# STM32U545 register map
File version: 1.0
CPU: CM33 r0p1, little endian, MPU, FPU, 4 interrupt priority bits
Registers are 32-bit, read-write, reset 0x0 unless marked. A register's access mark holds for its fields unless they carry their own. Offsets are from the block's base; [hi:lo] are bit positions; {n}, {i} and the like mark numbered series; 'fields as' and 'values as' point back to an identical list; <NAME> marks a mode.

## RCC (part 1 of 3) — Reset and clock control
Base 0x46020C00
Same registers: SEC_RCC 0x56020C00
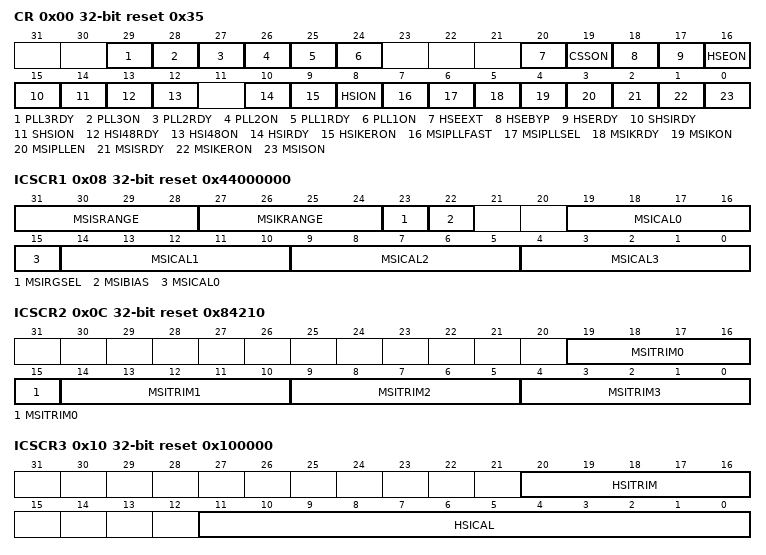
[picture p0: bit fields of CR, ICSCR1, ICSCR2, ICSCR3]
0x00 CR access per field reset 0x35 — RCC clock control register
  [29] PLL3RDY ro — PLL3 clock ready flag This bit is set by hardware to indicate that the PLL3 is locked.
    0=Unlocked (PLL3 unlocked); 1=Locked (PLL3 locked)
  [28] PLL3ON rw — PLL3 enable This bit is set and cleared by software to enable PLL3. It is cleared by hardware when entering Stop, Standby, or Shutdown mode.
    0=Disabled (PLL3 OFF); 1=Enabled (PLL3 ON)
  [27] PLL2RDY ro — PLL2 clock ready flag This bit is set by hardware to indicate that the PLL2 is locked.
    0=Unlocked (PLL2 unlocked); 1=Locked (PLL2 locked)
  [26] PLL2ON rw — PLL2 enable This bit is set and cleared by software to enable PLL2. It is cleared by hardware when entering Stop, Standby, or Shutdown mode.
    0=Disabled (PLL2 OFF); 1=Enabled (PLL2 ON)
  [25] PLL1RDY ro — PLL1 clock ready flag This bit is set by hardware to indicate that the PLL1 is locked.
    0=Unlocked (PLL1 unlocked); 1=Locked (PLL1 locked)
  [24] PLL1ON rw — PLL1 enable This bit is set and cleared by software to enable the main PLL. It is cleared by hardware when entering Stop, Standby, or Shutdown mode. This bit cannot be reset if the PLL1 clock is used as the system clock.
    0=Disabled (PLL1 OFF); 1=Enabled (PLL1 ON)
  [20] HSEEXT rw — HSE external clock bypass mode This bit is set and reset by software to select the external clock mode in bypass mode. External clock mode must be configured with HSEON bit to be used by the device. This bit can be written only if the HSE oscillator is disabled. This bit is active only if the HSE bypass mode is enabled.
    0=Analog (external HSE clock analog mode); 1=Digital (external HSE clock digital mode (through I/O Schmitt trigger))
  [19] CSSON rw — Clock security system enable This bit is set by software to enable the clock security system. When CSSON is set, the clock detector is enabled by hardware when the HSE oscillator is ready, and disabled by hardware if a HSE clock failure is detected. This bit is set only and is cleared by reset.
    0=Disabled (Clock security system OFF (clock detector OFF)); 1=Enabled (Clock security system ON (Clock detector ON if the HSE oscillator is stable, OFF if not))
  [18] HSEBYP rw — HSE crystal oscillator bypass This bit is set and cleared by software to bypass the oscillator with an external clock. The�external clock must be enabled with the HSEON bit set, to be used by the device. This�bit can be written only if the HSE oscillator is disabled.
    0=NotBypassed (HSE crystal oscillator not bypassed); 1=Bypassed (HSE crystal oscillator bypassed with external clock)
  [17] HSERDY ro — HSE clock ready flag This bit is set by hardware to indicate that the HSE oscillator is stable. Note: Once the HSEON bit is cleared, HSERDY goes low after six HSE clock cycles.
    0=NotReady (HSE oscillator not ready); 1=Ready (HSE oscillator ready)
  [16] HSEON rw — HSE clock enable This bit is set and cleared by software. It is cleared by hardware to stop the HSE oscillator when entering Stop, Standby, or Shutdown mode. This bit cannot be reset if the HSE oscillator is used directly or indirectly as the system clock.
    0=Disabled (HSE oscillator off); 1=Enabled (HSE oscillator on)
  [15] SHSIRDY ro — SHSI clock ready flag This bit is set by hardware to indicate that the SHSI oscillator is stable. It is set only when SHSI is enabled by software (by setting SHSION). Note: Once the SHSION bit is cleared, SHSIRDY goes low after six SHSI clock cycles.
    0=NotReady (SHSI oscillator not ready); 1=Ready (SHSI oscillator ready)
  [14] SHSION rw — SHSI clock enable This bit is set and cleared by software. It is cleared by hardware to stop the SHSI when entering in Stop, Standby, or Shutdown modes.
    0=Disabled (SHSI oscillator off); 1=Enabled (SHSI oscillator on)
  [13] HSI48RDY ro — HSI48 clock ready flag This bit is set by hardware to indicate that HSI48 oscillator is stable. Itis set only when HSI48 is enabled by software (by setting HSI48ON).
    0=NotReady (HSI48 oscillator not ready); 1=Ready (HSI48 oscillator ready)
  [12] HSI48ON rw — HSI48 clock enable This bit is set and cleared by software. It is cleared by hardware to stop the HSI48 when entering in Stop, Standby, or Shutdown modes.
    0=Disabled (HSI48 oscillator off); 1=Enabled (HSI48 oscillator on)
  [10] HSIRDY ro — HSI16 clock ready flag This bit is set by hardware to indicate that HSI16 oscillator is stable. It is set only when HSI16 is enabled by software (by setting HSION). Note: Once the HSION bit is cleared, HSIRDY goes low after six HSI16 clock cycles.
    0=NotReady (HSI16 oscillator not ready); 1=Ready (HSI16 oscillator ready)
  [9] HSIKERON rw — HSI16 enable for some peripheral kernels This bit is set and cleared by software to force HSI16 ON even in Stop modes. Keeping HSI16 on in Stop mode allows the communication speed not to be reduced by the HSI16 startup time. This bit has no effect on HSION value. Refer to Section�11.4.24 for more details. This bit must be configured at 0 before entering Stop 3 mode.
    0=NotForced (No effect on HSI16 oscillator); 1=Forced (HSI16 oscillator forced on even in Stop mode)
  [8] HSION rw — HSI16 clock enable This bit is set and cleared by software. It is cleared by hardware to stop the HSI16 oscillator when entering Stop, Standby, or Shutdown mode. This bit is set by hardware to force the�HSI16 oscillator on when STOPWUCK = 1 when leaving Stop modes, or in case of failure of the HSE crystal oscillator. This bit is set by hardware if the HSI16 is used directly or indirectly as system clock.
    0=Disabled (HSI16 oscillator off); 1=Enabled (HSI16 oscillator on)
  [7] MSIPLLFAST rw — MSI PLL mode fast startup This bit is set and reset by software to enable/disable the fast PLL mode start-up of the MSI clock source. This bit is used only if PLL mode is selected (MSIPLLEN = 1). The fast start-up feature is not active the first time the PLL mode is selected. The�fast start-up is active when the MSI in PLL mode returns from switch off.
    0=Normal (MSI PLL normal start-up); 1=Fast (MSI PLL fast start-up)
  [6] MSIPLLSEL rw — MSI clock with PLL mode selection This bit is set and cleared by software to select which MSI output clock uses the PLL mode. It�can be written only when the MSI PLL mode is disabled (MSIPLLEN = 0). Note: If the MSI kernel clock output uses the same oscillator source than the MSI system clock output, then the PLL mode is applied to both clock outputs.
    0=MSIK (PLL mode applied to MSIK (MSI kernel) clock output); 1=MSIS (PLL mode applied to MSIS (MSI system) clock output)
  [5] MSIKRDY ro — MSIK clock ready flag This bit is set by hardware to indicate that the MSIK is stable. It is set only when MSI kernel oscillator is enabled by software by setting MSIKON. Note: Once MSIKON bit is cleared, MSIKRDY goes low after six MSIK oscillator clock cycles.
    0=NotReady (MSIK (MSI kernel) oscillator not ready); 1=Ready (MSIK (MSI kernel) oscillator ready)
  [4] MSIKON rw — MSIK clock enable This bit is set and cleared by software. It is cleared by hardware to stop the MSIK when entering Stop, Standby, or Shutdown mode. This bit is set by hardware to force the MSIK oscillator ON when exiting Standby or Shutdown mode. It is set by hardware to force the MSIK oscillator on when STOPWUCK = 0 or STOPKERWUCK�=�0 when exiting Stop modes, or in case of a failure of the HSE oscillator.
    0=Disabled (MSIK (MSI kernel) oscillator disabled); 1=Enabled (MSIK (MSI kernel) oscillator enabled)
  [3] MSIPLLEN rw — MSI clock PLL-mode enable This bit is set and cleared by software to enable/disable the PLL part of the MSI clock source. MSIPLLEN must be enabled after LSE is enabled (LSEON enabled) and ready (LSERDY set by hardware). A hardware protection prevents from enabling MSIPLLEN if LSE is not ready. This bit is cleared by hardware when LSE is disabled (LSEON = 0) or when the CSS on LSE detects a LSE failure (see RCC_CSR).
    0=Disabled (MSI PLL-mode OFF); 1=Enabled (MSI PLL-mode ON)
  [2] MSISRDY ro — MSIS clock ready flag This bit is set by hardware to indicate that the MSIS oscillator is stable. It is set only when MSIS is enabled by software (by setting MSISON). Note: Once the MSISON bit is cleared, MSISRDY goes low after six MSIS clock cycles.
    0=NotReady (MSIS (MSI system) oscillator not ready); 1=Ready (MSIS (MSI system) oscillator ready)
  [1] MSIKERON rw — MSI enable for some peripheral kernels This bit is set and cleared by software to force MSI ON even in Stop modes. Keeping the MSI on in Stop mode allows the communication speed not to be reduced by the MSI startup time. This bit has no effect on MSISON and MSIKON values (see Section�11.4.24 for more details). This bit must be configured at 0 before entering Stop 3 mode.
    0=NotForced (No effect on MSI oscillator); 1=Forced (MSI oscillator forced ON even in Stop mode)
  [0] MSISON rw — MSIS clock enable This bit is set and cleared by software. It is cleared by hardware to stop the MSIS oscillator when entering Stop, Standby or Shutdown mode. This bit is set by hardware to force the�MSIS oscillator on when exiting Standby or Shutdown mode. It is set by hardware to force the MSIS oscillator ON when STOPWUCK = 0 when exiting Stop modes, or in case of a failure of the HSE oscillator. Set by hardware when used directly or indirectly as system clock.
    0=Disabled (MSIS (MSI system) oscillator off); 1=Enabled (MSIS (MSI system) oscillator on)
0x08 ICSCR1 access per field reset 0x44000000 (reset mask 0xFFF00000) — RCC internal clock sources calibration register 1
  [31:28] MSISRANGE rw — MSIS clock ranges These bits are configured by software to choose the frequency range of MSIS oscillator when MSIRGSEL is set. 16 frequency ranges are available: Note: MSISRANGE can be modified when MSIS is off (MSISON = 0) or when MSIS is ready (MSISRDY�=�1). MSISRANGE must NOT be modified when MSIS is on and NOT ready (MSISON�=�1 and MSISRDY�=�0) Note: MSISRANGE is kept when the device wakes up from Stop mode, except when the�MSIS range is above 24 MHz. In this case MSISRANGE is changed by hardware into range 2 (24 MHz).
    0=f_48MHz (Range 0 around 48 MHz); 1=f_24MHz (Range 1 around 24 MHz); 2=f_16MHz (Range 2 around 16 MHz); 3=f_12MHz (Range 3 around 12 MHz); 4=f_4MHz (Range 4 around 4 MHz); 5=f_2MHz (Range 5 around 2 MHz); 6=f_1_333MHz (Range 6 around 1.33 MHz); 7=f_1MHz (Range 7 around 1 MHz); 8=f_3_072MHz (Range 8 around 3.072 MHz); 9=f_1_536MHz (Range 9 around 1.536 MHz); 10=f_1_024MHz (Range 10 around 1.024 MHz); 11=f_768kHz (Range 11 around 768 kHz); 12=f_400kHz (Range 12 around 400 kHz); 13=f_200kHz (Range 13 around 200 kHz); 14=f_133kHz (Range 14 around 133 kHz); 15=f_100kHz (Range 15 around 100 kHz)
  [27:24] MSIKRANGE rw — MSIK clock ranges These bits are configured by software to choose the frequency range of MSIK oscillator when MSIRGSEL is set. 16 frequency ranges are available: Note: MSIKRANGE can be modified when MSIK is off (MSISON = 0) or when MSIK is ready (MSIKRDY�=�1). MSIKRANGE must NOT be modified when MSIK is on and NOT ready (MSIKON = 1 and MSIKRDY = 0) Note: MSIKRANGE is kept when the device wakes up from Stop mode, except when the�MSIK range is above 24 MHz. In this case MSIKRANGE is changed by hardware into�range 2 (24 MHz).
    values as MSISRANGE
  [23] MSIRGSEL rw — MSI clock range selection This bit is set by software to select the MSIS and MSIK clocks range with MSISRANGE[3:0] and MSIKRANGE[3:0]. Write 0 has no effect. After exiting Standby or Shutdown mode, or after a reset, this bit is at 0 and the MSIS and MSIK ranges are provided by MSISSRANGE[3:0] and MSIKSRANGE[3:0] in RCC_CSR.
    0=CSR (MSIS/MSIK ranges provided by MSISSRANGE[3:0] and MSIKSRANGE[3:0] in RCC_CSR); 1=ICSCR1 (MSIS/MSIK ranges provided by MSISRANGE[3:0] and MSIKRANGE[3:0] in RCC_ICSCR1)
  [22] MSIBIAS rw — MSI bias mode selection This bit is set by software to select the MSI bias mode. By default, the MSI bias is in�continuous mode in order to maintain the output clocks accuracy. Setting this bit reduces the MSI consumption when the regulator is in range 4, or when the device is in Stop 1 or Stop�2 mode, but it�decreases the MSI accuracy
    0=Continuous (MSI bias continuous mode (clock accuracy fast settling time)); 1=Sampling (MSI bias sampling mode when the regulator is in range 4, or when the device is in Stop 1 or Stop 2 (ultra-low-power mode))
  [19:15] MSICAL0 ro — MSIRC0 clock calibration for MSI ranges 0 to 3 These bits are initialized at startup with the factory-programmed MSIRC0 calibration trim value for ranges 0 to 3. When MSITRIM0 is written, MSICAL0 is updated with the sum of MSITRIM0[4:0] and the factory-programmed calibration trim value MSIRC0[4:0]. There is no hardware protection to limit a potential overflow due to the addition of MSITRIM bitfield and factory program bitfield for this calibration value. Control must be managed by software at user level.
  [14:10] MSICAL1 ro — MSIRC1 clock calibration for MSI ranges 4 to 7 These bits are initialized at startup with the factory-programmed MSIRC1 calibration trim value for ranges 4 to 7. When MSITRIM1 is written, MSICAL1 is updated with the sum of MSITRIM1[4:0] and the factory calibration trim value MSIRC1[4:0]. There is no hardware protection to limit a potential overflow due to the addition of MSITRIM bitfield and factory program bitfield for this calibration value. Control must be managed by software at user level.
  [9:5] MSICAL2 ro — MSIRC2 clock calibration for MSI ranges 8 to 11 These bits are initialized at startup with the factory-programmed MSIRC2 calibration trim value for ranges 8 to 11. When MSITRIM2 is written, MSICAL2 is updated with the sum of MSITRIM2[4:0] and the factory calibration trim value MSIRC2[4:0]. There is no hardware protection to limit a potential overflow due to the addition of MSITRIM bitfield and factory program bitfield for this calibration value. Control must be managed by software at user level.
  [4:0] MSICAL3 ro — MSIRC3 clock calibration for MSI ranges 12 to 15 These bits are initialized at startup with the factory-programmed MSIRC3 calibration trim value for ranges 12 to 15. When MSITRIM3 is written, MSICAL3 is updated with the sum of MSITRIM3[4:0] and the factory calibration trim value MSIRC2[4:0]. There is no hardware protection to limit a potential overflow due to the addition of MSITRIM bitfield and factory program bitfield for this calibration value. Control must be managed by software at user level.
0x0C ICSCR2 reset 0x84210 — RCC internal clock sources calibration register 2
  [19-5n:15-5n] MSITRIM{n} (n=0..3) — MSI clock trimming for ranges {4n} to {4n+3} These bits provide an additional user-programmable trimming value that is added to the factory-programmed calibration trim value MSIRC{n}[4:0] bits. It can be programmed to adjust to voltage and temperature variations that influence the frequency of the MSI.
0x10 ICSCR3 access per field reset 0x100000 (reset mask 0xFFFFF000) — RCC internal clock sources calibration register 3
  [20:16] HSITRIM rw — HSI clock trimming These bits provide an additional user-programmable trimming value that is added to HSICAL[11:0] bits. It can be programmed to adjust to voltage and temperature variations that influence the frequency of the HSI.
  [11:0] HSICAL ro — HSI clock calibration These bits are initialized at startup with the factory-programmed HSI calibration trim value. When HSITRIM is written, HSICAL is updated with the sum of HSITRIM and the factory trim value.
0x14 CRRCR ro (reset mask 0xFFFFF000) — RCC clock recovery RC register
  [8:0] HSI48CAL — HSI48 clock calibration These bits are initialized at startup with the factory-programmed HSI48 calibration trim value.
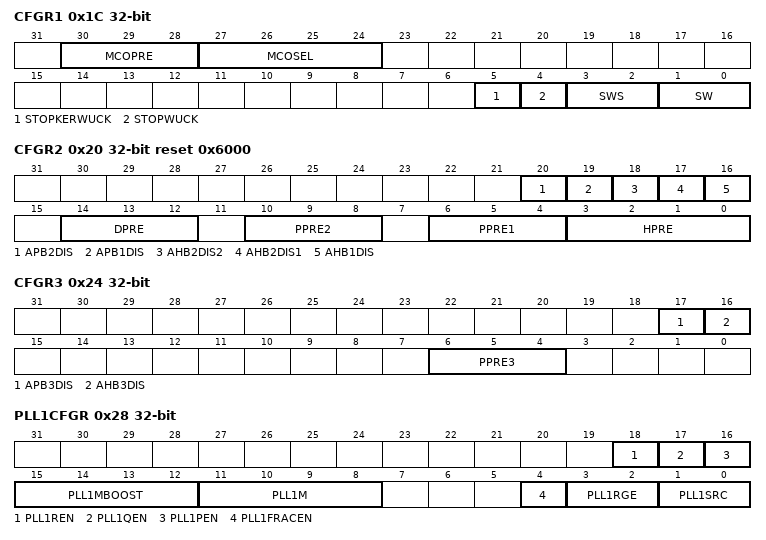
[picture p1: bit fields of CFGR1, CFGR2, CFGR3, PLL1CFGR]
0x1C CFGR1 access per field — RCC clock configuration register 1
  [30:28] MCOPRE rw — microcontroller clock output prescaler This bitfield is set and cleared by software. It is highly recommended to change this prescaler before MCO output is enabled. Others: not allowed
    0=Div1 (MCO divided by 1); 1=Div2 (MCO divided by 2); 2=Div4 (MCO divided by 4); 3=Div8 (MCO divided by 8); 4=Div16 (MCO divided by 16)
  [27:24] MCOSEL rw — microcontroller clock output This bitfield is set and cleared by software. Others: reserved Note: This clock output may have some truncated cycles at startup or during MCO clock source switching.
    0=None (MCO output disabled, no clock on MCO); 1=SYSCLK (SYSCLK system clock selected); 2=MSIS (MSIS clock selected); 3=HSI16 (HSI16 clock selected); 4=HSE (HSE clock selected); 5=PLL (Main PLL clock pll1_r_ck selected); 6=LSI (LSI clock selected); 7=LSE (LSE clock selected); 8=HSI48 (Internal HSI48 clock selected); 9=MSIK (MSIK clock selected)
  [5] STOPKERWUCK rw — wake-up from Stop kernel clock automatic enable selection This bit is set and cleared by software to enable automatically another oscillator when exiting Stop mode. This oscillator can be used as independent kernel clock by peripherals.
    0=MSIK (MSIK oscillator automatically enabled when exiting Stop mode or when a CSS on HSE event occurs.); 1=HSI16 (HSI16 oscillator automatically enabled when exiting Stop mode or when a CSS on HSE event occurs.)
  [4] STOPWUCK rw — wake-up from Stop and CSS backup clock selection This bit is set and cleared by software to select the system clock used when exiting Stop mode. The selected clock is also used as emergency clock for the clock security system on�HSE. STOPWUCK must not be modified when the CSS is enabled by HSECSSON in�RCC_CR, and the system clock is HSE (SWS = 10) or a switch on HSE is�requested (SW�=�10).
    0=MSIS (MSIS oscillator selected as wake-up from stop clock and CSS backup clock); 1=HSI16 (HSI16 oscillator selected as wake-up from stop clock and CSS backup clock)
  [3:2] SWS ro — system clock switch status This bitfield is set and cleared by hardware to indicate which clock source is used as system clock.
    0=MSIS (MSIS oscillator used as system clock); 1=HSI16 (HSI16 oscillator used as system clock); 2=HSE (HSE used as system clock); 3=PLL (PLL pll1_r_ck used as system clock)
  [1:0] SW rw — system clock switch This bitfield is set and cleared by software to select system clock source (SYSCLK). It is configured by hardware to force MSIS oscillator selection when exiting Standby or Shutdown mode. This bitfield is configured by hardware to force MSIS or HSI16 oscillator selection when exiting Stop mode or in case of HSE oscillator failure, depending on STOPWUCK.
    0=MSIS (MSIS selected as system clock); 1=HSI16 (HSI16 selected as system clock); 2=HSE (HSE selected as system clock); 3=PLL (PLL pll1_r_ck selected as system clock)
0x20 CFGR2 reset 0x6000 — RCC clock configuration register 2
  [20] APB2DIS — APB2 clock disable This bit can be set in order to further reduce power consumption, when none of the APB2 peripherals are used and when their clocks are disabled in RCC_APB2ENR. When this bit is set, all APB2 peripherals clocks are off.
    0=Enabled (APB2 clock enabled, distributed to peripherals according to their dedicated clock enable control bits); 1=Disabled (APB2 clock disabled)
  [19] APB1DIS — APB1 clock disable This bit can be set in order to further reduce power consumption, when none of the APB1 peripherals (except IWDG) are used and when their clocks are disabled in RCC_APB1ENR. When this bit is set, all the APB1 peripherals clocks are off, except for IWDG.
    0=Enabled (APB1 clock enabled, distributed to peripherals according to their dedicated clock enable control bits); 1=Disabled (APB1 clock disabled)
  [18] AHB2DIS2 — AHB2_2 clock disable This bit can be set in order to further reduce power consumption, when none of the AHB2 peripherals from RCC_AHB2ENR2 are used and when their clocks are disabled in RCC_AHB2ENR2. When this bit is set, all the AHB2 peripherals clocks from RCC_AHB2ENR2 are off.
    0=Enabled (AHB2_2 clock enabled, distributed to peripherals according to their dedicated clock enable control bits); 1=Disabled (AHB2_2 clock disabled)
  [17] AHB2DIS1 — AHB2_1 clock disable This bit can be set in order to further reduce power consumption, when none of the AHB2 peripherals from RCC_AHB2ENR1 (except SRAM2 and SRAM3) are used and when their clocks are disabled in RCC_AHB2ENR1. When this bit is set, all the AHB2 peripherals clocks from RCC_AHB2ENR1 are off, except for SRAM2 and SRAM3.
    0=Enabled (AHB2_1 clock enabled, distributed to peripherals according to their dedicated clock enable control bits); 1=Disabled (AHB2_1 clock disabled)
  [16] AHB1DIS — AHB1 clock disable This bit can be set in order to further reduce power consumption, when none of the AHB1 peripherals (except those listed hereafter) are used and when their clocks are disabled in RCC_AHB1ENR. When this bit is set, all the AHB1 peripherals clocks are off, except for FLASH, BKPSRAM, ICACHE, DCACHE1 and SRAM1.
    0=Enabled (AHB1 clock enabled, distributed to peripherals according to their dedicated clock enable control bits); 1=Disabled (AHB1 clock disabled)
  [14:12] DPRE — DSI PHY prescaler This bitfiled is set and cleared by software to control the division factor of DSI PHY bus clock (DCLK). 0xx: DCLK not divided Note: This bitfield is only available on some devices in the STM32U5 Series. Refer to the device datasheet for availability of its associated peripheral. If not present, consider this bitfield as reserved and keep it at reset value.
    4=Div2 (DCLK divided by 2); 5=Div4 (DCLK divided by 4); 6=Div8 (DCLK divided by 8); 7=Div16 (DCLK divided by 16); other=Div1 (DCLK not divided)
  [10:8] PPRE2 — APB2 prescaler This bitfiled is set and cleared by software to control the division factor of APB2 clock (PCLK2). 0xx: PCLK2 not divided
    4=Div2 (PCLK divided by 2); 5=Div4 (PCLK divided by 4); 6=Div8 (PCLK divided by 8); 7=Div16 (PCLK divided by 16); other=Div1 (PCLK not divided)
  [6:4] PPRE1 — APB1 prescaler This bitfiled is set and cleared by software to control the division factor of APB1 clock (PCLK1). 0xx: PCLK1 not divided
    values as PPRE2
  [3:0] HPRE — AHB prescaler This bitfiled is set and cleared by software to control the division factor of the AHB clock (HCLK). Depending on the device voltage range, the software must set these bits correctly to ensure that the system frequency does not exceed the maximum allowed frequency (for more details, refer to Table�118). After a write operation to these bits and before decreasing the voltage range, this register must be read to be sure that the new value is taken into account. 0xxx: SYSCLK not divided
    8=Div2 (HCLK divided by 2); 9=Div4 (HCLK divided by 4); 10=Div8 (HCLK divided by 8); 11=Div16 (HCLK divided by 16); 12=Div64 (HCLK divided by 64); 13=Div128 (HCLK divided by 128); 14=Div256 (HCLK divided by 256); 15=Div512 (HCLK divided by 512); other=Div1 (HCLK not divided)
0x24 CFGR3 — RCC clock configuration register 3
  [17] APB3DIS — APB3 clock disable This bit can be set in order to further reduce power consumption, when none of the APB3 peripherals from RCC_APB3ENR are used and when their clocks are disabled in RCC_APB3ENR. When this bit is set, all the APB3 peripherals clocks are off.
    0=Enabled (APB3 clock enabled, distributed to peripherals according to their dedicated clock enable control bits); 1=Disabled (APB3 clock disabled)
  [16] AHB3DIS — AHB3 clock disable This bit can be set in order to further reduce power consumption, when none of the AHB3 peripherals (except SRAM4) are used and when their clocks are disabled in RCC_AHB3ENR. When this bit is set, all the AHB3 peripherals clocks are off, except for SRAM4.
    0=Enabled (AHB3 clock enabled, distributed to peripherals according to their dedicated clock enable control bits); 1=Disabled (AHB3 clock disabled)
  [6:4] PPRE3 — APB3 prescaler This bitfield is set and cleared by software to control the division factor of the APB3 clock (PCLK3). 0xx: HCLK not divided
    values as CFGR2.PPRE2
0x28 PLL1CFGR — RCC PLL1 configuration register
  [18] PLL1REN — PLL1 DIVR divider output enable This bit is set and reset by software to enable the pll1_r_ck output of the PLL1. To save power, PLL1RENPLL2REN and PLL1R bits must be set to 0 when pll1_r_ck is not used. This bit can be cleared only when the PLL1 is not used as SYSCLK.
    0=Disabled (pllx_r_ck ready interrupt disabled); 1=Enabled (pllx_r_ck ready interrupt enabled)
  [17] PLL1QEN — PLL1 DIVQ divider output enable This bit is set and reset by software to enable the pll1_q_ck output of the PLL1. To save power, PLL1QEN and PLL1Q bits must be set to 0 when pll1_q_ck is not used.
    0=Disabled (pllx_q_ck output disabled); 1=Enabled (pllx_q_ck output enabled)
  [16] PLL1PEN — PLL1 DIVP divider output enable This bit is set and reset by software to enable the pll1_p_ck output of the PLL1. To save power, PLL1PEN and PLL1P bits must be set to 0 when pll1_p_ck is not used.
    0=Disabled (pllx_p_ck output disabled); 1=Enabled (pllx_p_ck output enabled)
  [15:12] PLL1MBOOST — Prescaler for EPOD booster input clock This bitfield is set and cleared by software to configure the prescaler of the PLL1, used for the EPOD booster. The EPOD booster input frequency is PLL1�input�clock�frequency/PLL1MBOOST. This bit can be written only when the PLL1 is disabled (PLL1ON = 0 and PLL1RDY = 0) and EPODboost mode is disabled (see Section�10: Power control (PWR)). others: reserved
    0=Div1 (division by 1 (bypass)); 1=Div2 (division by 2); 2=Div4 (division by 4); 3=Div6 (division by 6); 4=Div8 (division by 8); 5=Div10 (division by 10); 6=Div12 (division by 12); 7=Div14 (division by 14); 8=Div16 (division by 16)
  [11:8] PLL1M — Prescaler for PLL1 This bitfield is set and cleared by software to configure the prescaler of the PLL1. The VCO1 input frequency is PLL1 input clock frequency/PLL1M. This bit can be written only when the PLL1 is disabled (PLL1ON = 0 and PLL1RDY = 0). ...
    0=Div1 (division by 1 (bypass)); {v}=Div{v+1} (division by {v+1}) (v=1..15)
  [4] PLL1FRACEN — PLL1 fractional latch enable This bit is set and reset by software to latch the content of PLL1FRACN in the ΣΔ modulator. In order to latch the PLL1FRACN value into the ΣΔ modulator, PLL1FRACEN must be set to 0, then set to 1: the transition 0 to 1 transfers the content of PLL1FRACN into the modulator (see PLL initialization phase for details).
    0=NoEffect; 1=Latch (Content of PLLxFRACN latched in the Σ∆ modulator on PLLxFRACEN transition from 0 to 1)
  [3:2] PLL1RGE — PLL1 input frequency range This bit is set and reset by software to select the proper reference frequency range used for PLL1. It must be written before enabling the PLL1. 00-01-10: PLL1 input (ref1_ck) clock range frequency between 4 and 8 MHz
    3=Range2 (PLLx input (refx_ck) clock range frequency between 8 and 16 MHz); other=Range1 (PLLx input (refx_ck) clock range frequency between 4 and 8 MHz)
  [1:0] PLL1SRC — PLL1 entry clock source This bitfield is set and cleared by software to select PLL1 clock source. It can be written only when the PLL1 is disabled. In order to save power, when no PLL1 is used, this bitfield value must be zero.
    0=No clock sent to PLLx; 1=MSIS (MSIS clock selected as PLLx clock entry); 2=HSI16 (HSI16 clock selected as PLLx clock entry); 3=HSE (HSE clock selected as PLLx clock entry)
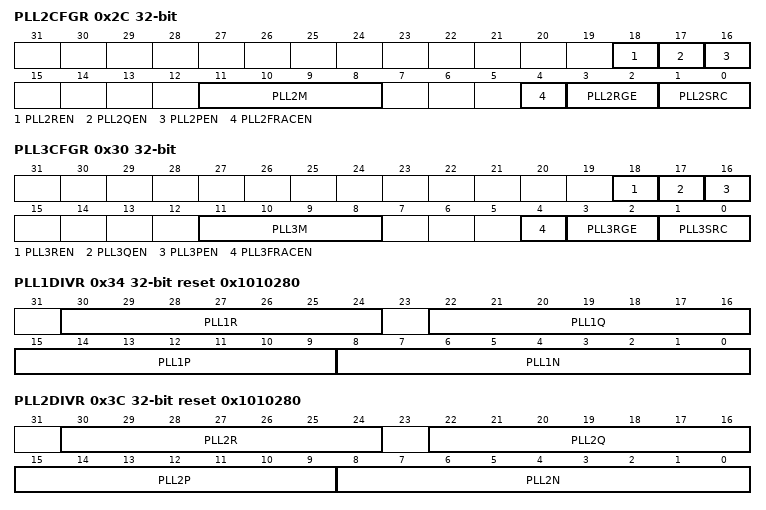
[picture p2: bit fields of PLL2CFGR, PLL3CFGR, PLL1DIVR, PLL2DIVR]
0x2C PLL2CFGR — RCC PLL2 configuration register
  [18] PLL2REN — PLL2 DIVR divider output enable This bit is set and reset by software to enable the pll2_r_ck output of the PLL2. To save power, PLL2REN and PLL2R bits must be set to 0 when pll2_r_ck is not used.
    values as PLL1CFGR.PLL1REN
  [17] PLL2QEN — PLL2 DIVQ divider output enable This bit is set and reset by software to enable the pll2_q_ck output of the PLL2. To save power, PLL2QEN and PLL2Q bits must be set to 0 when pll2_q_ck is not used.
    values as PLL1CFGR.PLL1QEN
  [16] PLL2PEN — PLL2 DIVP divider output enable This bit is set and reset by software to enable the pll2_p_ck output of the PLL2. To save power, PLL2PEN and PLL2P bits must be set to 0 when pll2_p_ck is not used.
    values as PLL1CFGR.PLL1PEN
  [11:8] PLL2M — Prescaler for PLL2 This bitfield is set and cleared by software to configure the prescaler of the PLL2. The VCO2 input frequency is PLL2 input clock frequency/PLL2M. This bit can be written only when the PLL2 is disabled (PLL2ON = 0 and PLL2RDY = 0). ...
    values as PLL1CFGR.PLL1M
  [4] PLL2FRACEN — PLL2 fractional latch enable This bit is set and reset by software to latch the content of PLL2FRACN in the ΣΔ modulator. In order to latch the PLL2FRACN value into the ΣΔ modulator, PLL2FRACEN must be set to 0, then set to 1: the transition 0 to 1 transfers the content of PLL2FRACN into the modulator (see PLL initialization phase for details).
    values as PLL1CFGR.PLL1FRACEN
  [3:2] PLL2RGE — PLL2 input frequency range This bitfield is set and reset by software to select the proper reference frequency range used for�PLL2. It must be written before enabling the PLL2. 00-01-10: PLL2 input (ref2_ck) clock range frequency between 4 and 8 MHz
    values as PLL1CFGR.PLL1RGE
  [1:0] PLL2SRC — PLL2 entry clock source This bitfield is set and cleared by software to select PLL2 clock source. It can be written only when the PLL2 is disabled. To save power, when no PLL2 is used, this bitfield value must be�zero.
    values as PLL1CFGR.PLL1SRC
0x30 PLL3CFGR — RCC PLL3 configuration register
  [18] PLL3REN — PLL3 DIVR divider output enable This bit is set and reset by software to enable the pll3_r_ck output of the PLL3. To save power, PLL3REN and PLL3R bits must be set to 0 when pll3_r_ck is not used.
    values as PLL1CFGR.PLL1REN
  [17] PLL3QEN — PLL3 DIVQ divider output enable This bit is set and reset by software to enable the pll3_q_ck output of the PLL3. To save power, PLL3QEN and PLL3Q bits must be set to 0 when pll3_q_ck is not used.
    values as PLL1CFGR.PLL1QEN
  [16] PLL3PEN — PLL3 DIVP divider output enable This bit is set and reset by software to enable the pll3_p_ck output of the PLL3. To save power, PLL3PEN and PLL3P bits must be set to 0 when pll3_p_ck is not used.
    values as PLL1CFGR.PLL1PEN
  [11:8] PLL3M — Prescaler for PLL3 This bitfield is set and cleared by software to configure the prescaler of the PLL3. The VCO3 input frequency is PLL3 input clock frequency/PLL3M. This bitfield can be written only when the PLL3 is disabled (PLL3ON = 0 and PLL3RDY = 0). ...
    values as PLL1CFGR.PLL1M
  [4] PLL3FRACEN — PLL3 fractional latch enable This bit is set and reset by software to latch the content of PLL3FRACN in the ΣΔ modulator. In order to latch the PLL3FRACN value into the ΣΔ modulator, PLL3FRACEN must be set to 0, then set to 1: the transition 0 to 1 transfers the content of PLL3FRACN into the modulator (see PLL initialization phase for details).
    values as PLL1CFGR.PLL1FRACEN
  [3:2] PLL3RGE — PLL3 input frequency range This bit is set and reset by software to select the proper reference frequency range used for�PLL3. It must be written before enabling the PLL3. 00-01-10: PLL3 input (ref3_ck) clock range frequency between 4 and 8 MHz
    values as PLL1CFGR.PLL1RGE
  [1:0] PLL3SRC — PLL3 entry clock source This bitfield is set and cleared by software to select PLL3 clock source. It can be written only when the PLL3 is disabled. To save power, when no PLL3 is used, this bitfield value must be�zero.
    values as PLL1CFGR.PLL1SRC
0x34 PLL1DIVR reset 0x1010280 — RCC PLL1 dividers register
  [30:24] PLL1R — PLL1 DIVR division factor This bitfield is set and reset by software to control frequency of the pll1_r_ck clock. It can be written only when the PLL1 is disabled (PLL1ON = 0 and PLL1RDY = 0). Only division by one and even division factors are allowed. ...
    0=Div1 (pllx_r_ck = vcox_ck); 1=Div2 (pllx_r_ck = vcox_ck / 2); 3=Div4 (pllx_r_ck = vcox_ck / 4); 5=Div6 (pllx_r_ck = vcox_ck / 6); 7=Div8 (pllx_r_ck = vcox_ck / 8); 9=Div10 (pllx_r_ck = vcox_ck / 10); 11=Div12 (pllx_r_ck = vcox_ck / 12); 13=Div14 (pllx_r_ck = vcox_ck / 14); 15=Div16 (pllx_r_ck = vcox_ck / 16); 17=Div18 (pllx_r_ck = vcox_ck / 18); 19=Div20 (pllx_r_ck = vcox_ck / 20); 21=Div22 (pllx_r_ck = vcox_ck / 22); 23=Div24 (pllx_r_ck = vcox_ck / 24); 25=Div26 (pllx_r_ck = vcox_ck / 26); 27=Div28 (pllx_r_ck = vcox_ck / 28); 29=Div30 (pllx_r_ck = vcox_ck / 30); 31=Div32 (pllx_r_ck = vcox_ck / 32); 33=Div34 (pllx_r_ck = vcox_ck / 34); 35=Div36 (pllx_r_ck = vcox_ck / 36); 37=Div38 (pllx_r_ck = vcox_ck / 38); 39=Div40 (pllx_r_ck = vcox_ck / 40); 41=Div42 (pllx_r_ck = vcox_ck / 42); 43=Div44 (pllx_r_ck = vcox_ck / 44); 45=Div46 (pllx_r_ck = vcox_ck / 46); 47=Div48 (pllx_r_ck = vcox_ck / 48); 49=Div50 (pllx_r_ck = vcox_ck / 50); 51=Div52 (pllx_r_ck = vcox_ck / 52); 53=Div54 (pllx_r_ck = vcox_ck / 54); 55=Div56 (pllx_r_ck = vcox_ck / 56); 57=Div58 (pllx_r_ck = vcox_ck / 58); 59=Div60 (pllx_r_ck = vcox_ck / 60); 61=Div62 (pllx_r_ck = vcox_ck / 62); 63=Div64 (pllx_r_ck = vcox_ck / 64); 65=Div66 (pllx_r_ck = vcox_ck / 66); 67=Div68 (pllx_r_ck = vcox_ck / 68); 69=Div70 (pllx_r_ck = vcox_ck / 70); 71=Div72 (pllx_r_ck = vcox_ck / 72); 73=Div74 (pllx_r_ck = vcox_ck / 74); 75=Div76 (pllx_r_ck = vcox_ck / 76); 77=Div78 (pllx_r_ck = vcox_ck / 78); 79=Div80 (pllx_r_ck = vcox_ck / 80); 81=Div82 (pllx_r_ck = vcox_ck / 82); 83=Div84 (pllx_r_ck = vcox_ck / 84); 85=Div86 (pllx_r_ck = vcox_ck / 86); 87=Div88 (pllx_r_ck = vcox_ck / 88); 89=Div90 (pllx_r_ck = vcox_ck / 90); 91=Div92 (pllx_r_ck = vcox_ck / 92); 93=Div94 (pllx_r_ck = vcox_ck / 94); 95=Div96 (pllx_r_ck = vcox_ck / 96); 97=Div98 (pllx_r_ck = vcox_ck / 98); 99=Div100 (pllx_r_ck = vcox_ck / 100); 101=Div102 (pllx_r_ck = vcox_ck / 102); 103=Div104 (pllx_r_ck = vcox_ck / 104); 105=Div106 (pllx_r_ck = vcox_ck / 106); 107=Div108 (pllx_r_ck = vcox_ck / 108); 109=Div110 (pllx_r_ck = vcox_ck / 110); 111=Div112 (pllx_r_ck = vcox_ck / 112); 113=Div114 (pllx_r_ck = vcox_ck / 114); 115=Div116 (pllx_r_ck = vcox_ck / 116); 117=Div118 (pllx_r_ck = vcox_ck / 118); 119=Div120 (pllx_r_ck = vcox_ck / 120); 121=Div122 (pllx_r_ck = vcox_ck / 122); 123=Div124 (pllx_r_ck = vcox_ck / 124); 125=Div126 (pllx_r_ck = vcox_ck / 126); 127=Div128 (pllx_r_ck = vcox_ck / 128)
  [22:16] PLL1Q — PLL1 DIVQ division factor This bitfield is set and reset by software to control the frequency of the pll1_q_ck clock. It can be written only when the PLL1 is disabled (PLL1ON = 0 and PLL1RDY = 0). ...
    0=Div1 (pllx_q_ck = vcox_ck); 1=Div2 (pllx_q_ck = vcox_ck / 2); 3=Div4 (pllx_q_ck = vcox_ck / 4); 5=Div6 (pllx_q_ck = vcox_ck / 6); 7=Div8 (pllx_q_ck = vcox_ck / 8); 9=Div10 (pllx_q_ck = vcox_ck / 10); 11=Div12 (pllx_q_ck = vcox_ck / 12); 13=Div14 (pllx_q_ck = vcox_ck / 14); 15=Div16 (pllx_q_ck = vcox_ck / 16); 17=Div18 (pllx_q_ck = vcox_ck / 18); 19=Div20 (pllx_q_ck = vcox_ck / 20); 21=Div22 (pllx_q_ck = vcox_ck / 22); 23=Div24 (pllx_q_ck = vcox_ck / 24); 25=Div26 (pllx_q_ck = vcox_ck / 26); 27=Div28 (pllx_q_ck = vcox_ck / 28); 29=Div30 (pllx_q_ck = vcox_ck / 30); 31=Div32 (pllx_q_ck = vcox_ck / 32); 33=Div34 (pllx_q_ck = vcox_ck / 34); 35=Div36 (pllx_q_ck = vcox_ck / 36); 37=Div38 (pllx_q_ck = vcox_ck / 38); 39=Div40 (pllx_q_ck = vcox_ck / 40); 41=Div42 (pllx_q_ck = vcox_ck / 42); 43=Div44 (pllx_q_ck = vcox_ck / 44); 45=Div46 (pllx_q_ck = vcox_ck / 46); 47=Div48 (pllx_q_ck = vcox_ck / 48); 49=Div50 (pllx_q_ck = vcox_ck / 50); 51=Div52 (pllx_q_ck = vcox_ck / 52); 53=Div54 (pllx_q_ck = vcox_ck / 54); 55=Div56 (pllx_q_ck = vcox_ck / 56); 57=Div58 (pllx_q_ck = vcox_ck / 58); 59=Div60 (pllx_q_ck = vcox_ck / 60); 61=Div62 (pllx_q_ck = vcox_ck / 62); 63=Div64 (pllx_q_ck = vcox_ck / 64); 65=Div66 (pllx_q_ck = vcox_ck / 66); 67=Div68 (pllx_q_ck = vcox_ck / 68); 69=Div70 (pllx_q_ck = vcox_ck / 70); 71=Div72 (pllx_q_ck = vcox_ck / 72); 73=Div74 (pllx_q_ck = vcox_ck / 74); 75=Div76 (pllx_q_ck = vcox_ck / 76); 77=Div78 (pllx_q_ck = vcox_ck / 78); 79=Div80 (pllx_q_ck = vcox_ck / 80); 81=Div82 (pllx_q_ck = vcox_ck / 82); 83=Div84 (pllx_q_ck = vcox_ck / 84); 85=Div86 (pllx_q_ck = vcox_ck / 86); 87=Div88 (pllx_q_ck = vcox_ck / 88); 89=Div90 (pllx_q_ck = vcox_ck / 90); 91=Div92 (pllx_q_ck = vcox_ck / 92); 93=Div94 (pllx_q_ck = vcox_ck / 94); 95=Div96 (pllx_q_ck = vcox_ck / 96); 97=Div98 (pllx_q_ck = vcox_ck / 98); 99=Div100 (pllx_q_ck = vcox_ck / 100); 101=Div102 (pllx_q_ck = vcox_ck / 102); 103=Div104 (pllx_q_ck = vcox_ck / 104); 105=Div106 (pllx_q_ck = vcox_ck / 106); 107=Div108 (pllx_q_ck = vcox_ck / 108); 109=Div110 (pllx_q_ck = vcox_ck / 110); 111=Div112 (pllx_q_ck = vcox_ck / 112); 113=Div114 (pllx_q_ck = vcox_ck / 114); 115=Div116 (pllx_q_ck = vcox_ck / 116); 117=Div118 (pllx_q_ck = vcox_ck / 118); 119=Div120 (pllx_q_ck = vcox_ck / 120); 121=Div122 (pllx_q_ck = vcox_ck / 122); 123=Div124 (pllx_q_ck = vcox_ck / 124); 125=Div126 (pllx_q_ck = vcox_ck / 126); 127=Div128 (pllx_q_ck = vcox_ck / 128)
  [15:9] PLL1P — PLL1 DIVP division factor This bitfield is set and reset by software to control the frequency of the pll1_p_ck clock. It can be written only when the PLL1 is disabled (PLL1ON = 0 and PLL1RDY = 0). ...
    0=Div1 (pllx_p_ck = vcox_ck); 1=Div2 (pllx_p_ck = vcox_ck / 2); 3=Div4 (pllx_p_ck = vcox_ck / 4); 5=Div6 (pllx_p_ck = vcox_ck / 6); 7=Div8 (pllx_p_ck = vcox_ck / 8); 9=Div10 (pllx_p_ck = vcox_ck / 10); 11=Div12 (pllx_p_ck = vcox_ck / 12); 13=Div14 (pllx_p_ck = vcox_ck / 14); 15=Div16 (pllx_p_ck = vcox_ck / 16); 17=Div18 (pllx_p_ck = vcox_ck / 18); 19=Div20 (pllx_p_ck = vcox_ck / 20); 21=Div22 (pllx_p_ck = vcox_ck / 22); 23=Div24 (pllx_p_ck = vcox_ck / 24); 25=Div26 (pllx_p_ck = vcox_ck / 26); 27=Div28 (pllx_p_ck = vcox_ck / 28); 29=Div30 (pllx_p_ck = vcox_ck / 30); 31=Div32 (pllx_p_ck = vcox_ck / 32); 33=Div34 (pllx_p_ck = vcox_ck / 34); 35=Div36 (pllx_p_ck = vcox_ck / 36); 37=Div38 (pllx_p_ck = vcox_ck / 38); 39=Div40 (pllx_p_ck = vcox_ck / 40); 41=Div42 (pllx_p_ck = vcox_ck / 42); 43=Div44 (pllx_p_ck = vcox_ck / 44); 45=Div46 (pllx_p_ck = vcox_ck / 46); 47=Div48 (pllx_p_ck = vcox_ck / 48); 49=Div50 (pllx_p_ck = vcox_ck / 50); 51=Div52 (pllx_p_ck = vcox_ck / 52); 53=Div54 (pllx_p_ck = vcox_ck / 54); 55=Div56 (pllx_p_ck = vcox_ck / 56); 57=Div58 (pllx_p_ck = vcox_ck / 58); 59=Div60 (pllx_p_ck = vcox_ck / 60); 61=Div62 (pllx_p_ck = vcox_ck / 62); 63=Div64 (pllx_p_ck = vcox_ck / 64); 65=Div66 (pllx_p_ck = vcox_ck / 66); 67=Div68 (pllx_p_ck = vcox_ck / 68); 69=Div70 (pllx_p_ck = vcox_ck / 70); 71=Div72 (pllx_p_ck = vcox_ck / 72); 73=Div74 (pllx_p_ck = vcox_ck / 74); 75=Div76 (pllx_p_ck = vcox_ck / 76); 77=Div78 (pllx_p_ck = vcox_ck / 78); 79=Div80 (pllx_p_ck = vcox_ck / 80); 81=Div82 (pllx_p_ck = vcox_ck / 82); 83=Div84 (pllx_p_ck = vcox_ck / 84); 85=Div86 (pllx_p_ck = vcox_ck / 86); 87=Div88 (pllx_p_ck = vcox_ck / 88); 89=Div90 (pllx_p_ck = vcox_ck / 90); 91=Div92 (pllx_p_ck = vcox_ck / 92); 93=Div94 (pllx_p_ck = vcox_ck / 94); 95=Div96 (pllx_p_ck = vcox_ck / 96); 97=Div98 (pllx_p_ck = vcox_ck / 98); 99=Div100 (pllx_p_ck = vcox_ck / 100); 101=Div102 (pllx_p_ck = vcox_ck / 102); 103=Div104 (pllx_p_ck = vcox_ck / 104); 105=Div106 (pllx_p_ck = vcox_ck / 106); 107=Div108 (pllx_p_ck = vcox_ck / 108); 109=Div110 (pllx_p_ck = vcox_ck / 110); 111=Div112 (pllx_p_ck = vcox_ck / 112); 113=Div114 (pllx_p_ck = vcox_ck / 114); 115=Div116 (pllx_p_ck = vcox_ck / 116); 117=Div118 (pllx_p_ck = vcox_ck / 118); 119=Div120 (pllx_p_ck = vcox_ck / 120); 121=Div122 (pllx_p_ck = vcox_ck / 122); 123=Div124 (pllx_p_ck = vcox_ck / 124); 125=Div126 (pllx_p_ck = vcox_ck / 126); 127=Div128 (pllx_p_ck = vcox_ck / 128)
  [8:0] PLL1N range 3..511 — Multiplication factor for PLL1 VCO This bitfield is set and reset by software to control the multiplication factor of the VCO. It can be written only when the PLL is disabled (PLL1ON = 0 and PLL1RDY = 0). ... ... Others: reserved VCO output frequency = F<sub>ref1_ck</sub> x PLL1N, when fractional value 0 has been loaded in PLL1FRACN, with: PLL1N between 4 and 512 input frequency F<sub>ref1_ck</sub> between 4 and 16�MHz
0x38 PLL1FRACR — RCC PLL1 fractional divider register
  [15:3] PLL1FRACN range 0..511 — Fractional part of the multiplication factor for PLL1 VCO This bitfield is set and reset by software to control the fractional part of the VCO multiplication factor. It can be written at any time, allowing dynamic fine-tuning of the PLL1 VCO. VCO output frequency = F<sub>ref1_ck</sub> x (PLL1N + (PLL1FRACN / 2<sup>13</sup>)), with: PLL1N must be between 4 and 512. PLL1FRACN can be between 0 and 2<sup>13</sup>- 1. The input frequency F<sub>ref1_ck</sub> must be between 4 and 16 MHz. To change the FRACN value on-the-fly even if the PLL is enabled, the application must proceed as�follows: Set PLL1FRACEN = 0. Write the new fractional value into PLL1FRACN. Set PLL1FRACEN = 1.
0x3C PLL2DIVR reset 0x1010280 — RCC PLL2 dividers configuration register
  [30:24] PLL2R — PLL2 DIVR division factor This bitfield is set and reset by software to control the frequency of the pll2_r_ck clock. It can be written only when the PLL2 is disabled (PLL2ON = 0 and PLL2RDY = 0). ...
    values as PLL1DIVR.PLL1R
  [22:16] PLL2Q — PLL2 DIVQ division factor This bitfield is set and reset by software to control the frequency of the pll2_q_ck clock. It can be written only when the PLL2 is disabled (PLL2ON = 0 and PLL2RDY = 0). ...
    values as PLL1DIVR.PLL1Q
  [15:9] PLL2P — PLL2 DIVP division factor This bitfield is set and reset by software to control the frequency of the pll2_p_ck clock. It can be written only when the PLL2 is disabled (PLL2ON = 0 and PLL2RDY = 0). ...
    values as PLL1DIVR.PLL1P
  [8:0] PLL2N range 3..511 — Multiplication factor for PLL2 VCO This bitfield is set and reset by software to control the multiplication factor of the VCO. It can be written only when the PLL is disabled (PLL2ON = 0 and PLL2RDY = 0). ... ... Others: reserved VCO output frequency = F<sub>ref2_ck</sub> x PLL2N, when fractional value 0 has been loaded in PLL2FRACN, with: PLL2N between 4 and 512 input frequency F<sub>ref2_ck</sub> between 1MHz and 16MHz
0x40 PLL2FRACR — RCC PLL2 fractional divider register
  [15:3] PLL2FRACN range 0..511 — Fractional part of the multiplication factor for PLL2 VCO This bitfield is set and reset by software to control the fractional part of the VCO multiplication factor. It can be written at any time, allowing dynamic fine-tuning of the PLL2 VCO. VCO output frequency = F<sub>ref2_ck</sub> x (PLL2N + (PLL2FRACN / 2<sup>13</sup>)), with PLL2N must be between 4 and 512. PLL2FRACN can be between 0 and 2<sup>13 </sup>- 1. The input frequency F<sub>ref2_ck</sub> must be between 4 and 16 MHz. In order to change the FRACN value on-the-fly even if the PLL is enabled, the application must proceed as follows: Set the bit PLL2FRACEN to 0. Write the new fractional value into PLL2FRACN. Set the bit PLL2FRACEN to 1.
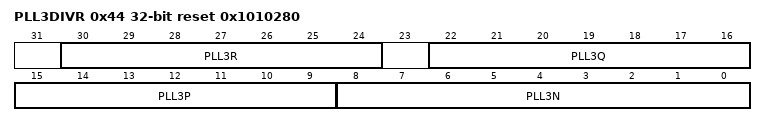
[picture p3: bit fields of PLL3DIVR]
0x44 PLL3DIVR reset 0x1010280 — RCC PLL3 dividers configuration register
  [30:24] PLL3R — PLL3 DIVR division factor This bitfield is set and reset by software to control the frequency of the pll3_r_ck clock. It can be written only when the PLL3 is disabled (PLL3ON = 0 and PLL3RDY = 0). ...
    values as PLL1DIVR.PLL1R
  [22:16] PLL3Q — PLL3 DIVQ division factor This bitfield is set and reset by software to control the frequency of the pll3_q_ck clock. It can be written only when the PLL3 is disabled (PLL3ON = 0 and PLL3RDY = 0). ...
    values as PLL1DIVR.PLL1Q
  [15:9] PLL3P — PLL3 DIVP division factor This bitfield is set and reset by software to control the frequency of the pll3_p_ck clock. It can be written only when the PLL3 is disabled (PLL3ON = 0 and PLL3RDY = 0). ...
    values as PLL1DIVR.PLL1P
  [8:0] PLL3N range 3..511 — Multiplication factor for PLL3 VCO This bitfield is set and reset by software to control the multiplication factor of the VCO. It can be written only when the PLL is disabled (PLL3ON = 0 and PLL3RDY = 0). ... ... Others: reserved VCO output frequency = F<sub>ref3_ck</sub> x PLL3N, when fractional value 0 has been loaded in PLL3FRACN, with: PLL3N between 4 and 512 input frequency F<sub>ref3_ck</sub> between 4 and 16MHz
